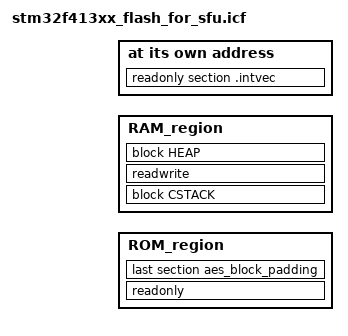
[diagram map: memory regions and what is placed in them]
/*###ICF### Section handled by ICF editor, don't touch! ****/
/*-Editor annotation file-*/
/* IcfEditorFile="$TOOLKIT_DIR$\config\ide\IcfEditor\cortex_v1_0.xml" */
/*-Specials-*/

define memory mem with size = 4G;

include "mapping_sbsfu.icf";
include "mapping_fwimg.icf";

define symbol __ICFEDIT_intvec_start__ = __ICFEDIT_region_SLOT_0_start__ + 512;
export symbol __ICFEDIT_intvec_start__;

/*-Memory Regions-*/
define symbol __ICFEDIT_region_ROM_start__ = __ICFEDIT_intvec_start__;
define symbol __ICFEDIT_region_ROM_end__   = __ICFEDIT_region_SLOT_0_end__;
define symbol __ICFEDIT_region_RAM_start__ = __ICFEDIT_SE_region_SRAM1_end__ + 1;
define symbol __ICFEDIT_region_RAM_end__   = 0x2004FFFF;

/* to make sure the binary size is a multiple of the AES block size (16 bytes) */
define root section aes_block_padding with alignment=16
{
udata8 "Force Alignment";
pad_to 16;
};

/*-Sizes-*/
define symbol __ICFEDIT_size_cstack__ = 0x2500;
/* heap +16k due to the size of the smallest sector */
define symbol __ICFEDIT_size_heap__   = 0x15000;

/**** End of ICF editor section. ###ICF###*/



/* Definition of the static memory section for the user configuration: TLS certificates, key, and wifi configuration data.
 * A whole sector must be reserved so that the linker does not place initialized data there, which 
 * would cause a sector erase when the firmware image is programmed.
 * This mapping is valid whatever the bank organization:
 *    Seen as 1 x 128k sector at 0x08020000 in single bank case
 *    Seen as 2 x 128k sectors at 0x08020000 in dual bank case.

 */
define symbol __ICFEDIT_region_FIXED_LOC_start__ = __ICFEDIT_region_SLOT_1_end__ + 1;
export symbol __ICFEDIT_region_FIXED_LOC_start__;

define region ROM_region      = mem:[from __ICFEDIT_region_ROM_start__   to __ICFEDIT_region_SLOT_0_end__];
define region RAM_region      = mem:[from __ICFEDIT_region_RAM_start__   to __ICFEDIT_region_RAM_end__];

 
define block CSTACK    with alignment = 8, size = __ICFEDIT_size_cstack__   { };
define block HEAP      with alignment = 8, size = __ICFEDIT_size_heap__     { };

initialize by copy { readwrite };
do not initialize  { section .noinit };

place at address mem:__ICFEDIT_intvec_start__ { readonly section .intvec };

place in ROM_region   { readonly , last section aes_block_padding};
place in RAM_region   { block CSTACK, 
                        readwrite,
                        block HEAP };
						
						
